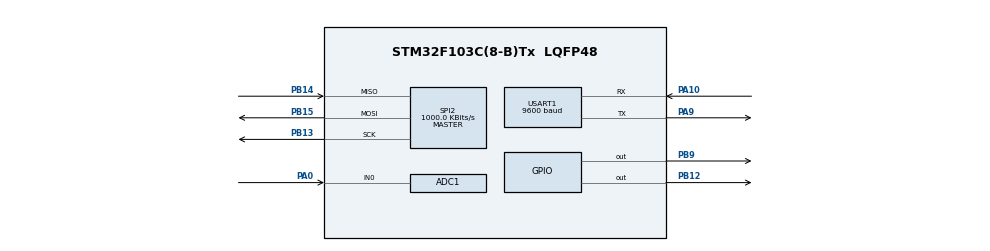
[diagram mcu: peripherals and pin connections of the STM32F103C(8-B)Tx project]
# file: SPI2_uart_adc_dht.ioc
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Mcu.Family=STM32F1
NVIC.ADC1_2_IRQn=true\:0\:0\:false\:false\:true\:true\:true
ADC1.Rank-0\#ChannelRegularConversion=1
PD1-OSC_OUT.Mode=HSE-External-Oscillator
PA10.Mode=Asynchronous
SPI2.VirtualType=VM_MASTER
ADC1.ContinuousConvMode=ENABLE
USART1.BaudRate=9600
PD0-OSC_IN.Signal=RCC_OSC_IN
PB15.Signal=SPI2_MOSI
PB13.Signal=SPI2_SCK
RCC.SYSCLKSource=RCC_SYSCLKSOURCE_HSE
ProjectManager.StackSize=0x400
PA0-WKUP.Signal=ADCx_IN0
PD1-OSC_OUT.Signal=RCC_OSC_OUT
PA13.Signal=SYS_JTMS-SWDIO
PA9.Mode=Asynchronous
ProjectManager.TargetToolchain=STM32CubeIDE
PA9.Signal=USART1_TX
SPI2.BaudRatePrescaler=SPI_BAUDRATEPRESCALER_8
PD0-OSC_IN.Mode=HSE-External-Oscillator
PB14.Signal=SPI2_MISO
ADC1.Channel-0\#ChannelRegularConversion=ADC_CHANNEL_0
board=custom
PB15.Mode=Full_Duplex_Master
RCC.APB2Freq_Value=8000000
PA14.Mode=Serial_Wire
PB14.Mode=Full_Duplex_Master
SPI2.CalculateBaudRate=1000.0 KBits/s
SH.ADCx_IN0.0=ADC1_IN0,IN0
ADC1.NbrOfConversion=1
PA13.Mode=Serial_Wire
Mcu.Name=STM32F103C(8-B)Tx
ADC1.SamplingTime-0\#ChannelRegularConversion=ADC_SAMPLETIME_239CYCLES_5
Mcu.Package=LQFP48
PB9.Signal=GPIO_Output
ADC1.master=1
SPI2.Mode=SPI_MODE_MASTER
USART1.VirtualMode=VM_ASYNC
PA10.Signal=USART1_RX
PA14.Signal=SYS_JTCK-SWCLK
ProjectManager.HeapSize=0x200
NVIC.PriorityGroup=NVIC_PRIORITYGROUP_4
ADC1.NbrOfConversionFlag=1
SPI2.Direction=SPI_DIRECTION_2LINES
PB13.Mode=Full_Duplex_Master
NVIC.USART1_IRQn=true\:0\:0\:false\:false\:true\:true\:true
RCC.APB1Freq_Value=8000000
PB12.Signal=GPIO_Output

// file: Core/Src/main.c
/* USER CODE BEGIN Header */
/**
  ******************************************************************************
  * @file           : main.c
  * @brief          : Main program body
  ******************************************************************************
  * @attention
  *
  * <h2><center>&copy; Copyright (c) 2022 STMicroelectronics.
  * All rights reserved.</center></h2>
  *
  * This software component is licensed by ST under BSD 3-Clause license,
  * the "License"; You may not use this file except in compliance with the
  * License. You may obtain a copy of the License at:
  *                        opensource.org/licenses/BSD-3-Clause
  *
  ******************************************************************************
  */
/* USER CODE END Header */
#include "main.h"

/* USER CODE BEGIN Includes */
#include "rc522.h"
#include "string.h"
#include "DHT.h"
#include "stdio.h"
/* USER CODE END Includes */

ADC_HandleTypeDef hadc1;

SPI_HandleTypeDef hspi2;

UART_HandleTypeDef huart1;

void SystemClock_Config(void);
static void MX_GPIO_Init(void);
static void MX_ADC1_Init(void);
static void MX_SPI2_Init(void);
static void MX_USART1_UART_Init(void);

int main(void)
{

  /* MCU Configuration--------------------------------------------------------*/

  /* Reset of all peripherals, Initializes the Flash interface and the Systick. */
  HAL_Init();

  /* Configure the system clock */
  SystemClock_Config();

  /* Initialize all configured peripherals */
  MX_GPIO_Init();
  MX_ADC1_Init();
  MX_SPI2_Init();
  MX_USART1_UART_Init();

  /* Infinite loop */
  while (1)
  {

  }
}

void SystemClock_Config(void)
{
  RCC_OscInitTypeDef RCC_OscInitStruct = {0};
  RCC_ClkInitTypeDef RCC_ClkInitStruct = {0};
  RCC_PeriphCLKInitTypeDef PeriphClkInit = {0};

  /** Initializes the RCC Oscillators according to the specified parameters
  * in the RCC_OscInitTypeDef structure.
  */
  RCC_OscInitStruct.OscillatorType = RCC_OSCILLATORTYPE_HSE;
  RCC_OscInitStruct.HSEState = RCC_HSE_ON;
  RCC_OscInitStruct.PLL.PLLState = RCC_PLL_NONE;
  if (HAL_RCC_OscConfig(&RCC_OscInitStruct) != HAL_OK)
  {
    Error_Handler();
  }
  /** Initializes the CPU, AHB and APB buses clocks
  */
  RCC_ClkInitStruct.ClockType = RCC_CLOCKTYPE_HCLK|RCC_CLOCKTYPE_SYSCLK
                              |RCC_CLOCKTYPE_PCLK1|RCC_CLOCKTYPE_PCLK2;
  RCC_ClkInitStruct.SYSCLKSource = RCC_SYSCLKSOURCE_HSE;
  RCC_ClkInitStruct.AHBCLKDivider = RCC_SYSCLK_DIV1;
  RCC_ClkInitStruct.APB1CLKDivider = RCC_HCLK_DIV1;
  RCC_ClkInitStruct.APB2CLKDivider = RCC_HCLK_DIV1;

  if (HAL_RCC_ClockConfig(&RCC_ClkInitStruct, FLASH_LATENCY_0) != HAL_OK)
  {
    Error_Handler();
  }
  PeriphClkInit.PeriphClockSelection = RCC_PERIPHCLK_ADC;
  PeriphClkInit.AdcClockSelection = RCC_ADCPCLK2_DIV2;
  if (HAL_RCCEx_PeriphCLKConfig(&PeriphClkInit) != HAL_OK)
  {
    Error_Handler();
  }
}

static void MX_ADC1_Init(void)
{

  ADC_ChannelConfTypeDef sConfig = {0};

  /** Common config
  */
  hadc1.Instance = ADC1;
  hadc1.Init.ScanConvMode = ADC_SCAN_DISABLE;
  hadc1.Init.ContinuousConvMode = ENABLE;
  hadc1.Init.DiscontinuousConvMode = DISABLE;
  hadc1.Init.ExternalTrigConv = ADC_SOFTWARE_START;
  hadc1.Init.DataAlign = ADC_DATAALIGN_RIGHT;
  hadc1.Init.NbrOfConversion = 1;
  if (HAL_ADC_Init(&hadc1) != HAL_OK)
  {
    Error_Handler();
  }
  /** Configure Regular Channel
  */
  sConfig.Channel = ADC_CHANNEL_0;
  sConfig.Rank = ADC_REGULAR_RANK_1;
  sConfig.SamplingTime = ADC_SAMPLETIME_239CYCLES_5;
  if (HAL_ADC_ConfigChannel(&hadc1, &sConfig) != HAL_OK)
  {
    Error_Handler();
  }

}

static void MX_SPI2_Init(void)
{

  /* SPI2 parameter configuration*/
  hspi2.Instance = SPI2;
  hspi2.Init.Mode = SPI_MODE_MASTER;
  hspi2.Init.Direction = SPI_DIRECTION_2LINES;
  hspi2.Init.DataSize = SPI_DATASIZE_8BIT;
  hspi2.Init.CLKPolarity = SPI_POLARITY_LOW;
  hspi2.Init.CLKPhase = SPI_PHASE_1EDGE;
  hspi2.Init.NSS = SPI_NSS_SOFT;
  hspi2.Init.BaudRatePrescaler = SPI_BAUDRATEPRESCALER_8;
  hspi2.Init.FirstBit = SPI_FIRSTBIT_MSB;
  hspi2.Init.TIMode = SPI_TIMODE_DISABLE;
  hspi2.Init.CRCCalculation = SPI_CRCCALCULATION_DISABLE;
  hspi2.Init.CRCPolynomial = 10;
  if (HAL_SPI_Init(&hspi2) != HAL_OK)
  {
    Error_Handler();
  }

}

static void MX_USART1_UART_Init(void)
{

  huart1.Instance = USART1;
  huart1.Init.BaudRate = 9600;
  huart1.Init.WordLength = UART_WORDLENGTH_8B;
  huart1.Init.StopBits = UART_STOPBITS_1;
  huart1.Init.Parity = UART_PARITY_NONE;
  huart1.Init.Mode = UART_MODE_TX_RX;
  huart1.Init.HwFlowCtl = UART_HWCONTROL_NONE;
  huart1.Init.OverSampling = UART_OVERSAMPLING_16;
  if (HAL_UART_Init(&huart1) != HAL_OK)
  {
    Error_Handler();
  }

}

static void MX_GPIO_Init(void)
{
  GPIO_InitTypeDef GPIO_InitStruct = {0};

  /* GPIO Ports Clock Enable */
  __HAL_RCC_GPIOD_CLK_ENABLE();
  __HAL_RCC_GPIOA_CLK_ENABLE();
  __HAL_RCC_GPIOB_CLK_ENABLE();

  /*Configure GPIO pin Output Level */
  HAL_GPIO_WritePin(GPIOB, GPIO_PIN_12|GPIO_PIN_9, GPIO_PIN_RESET);

  /*Configure GPIO pins : PB12 PB9 */
  GPIO_InitStruct.Pin = GPIO_PIN_12|GPIO_PIN_9;
  GPIO_InitStruct.Mode = GPIO_MODE_OUTPUT_PP;
  GPIO_InitStruct.Pull = GPIO_NOPULL;
  GPIO_InitStruct.Speed = GPIO_SPEED_FREQ_LOW;
  HAL_GPIO_Init(GPIOB, &GPIO_InitStruct);

}

void Error_Handler(void)
{
  __disable_irq();
  while (1)
  {
  }
}

/************************ (C) COPYRIGHT STMicroelectronics *****END OF FILE****/
